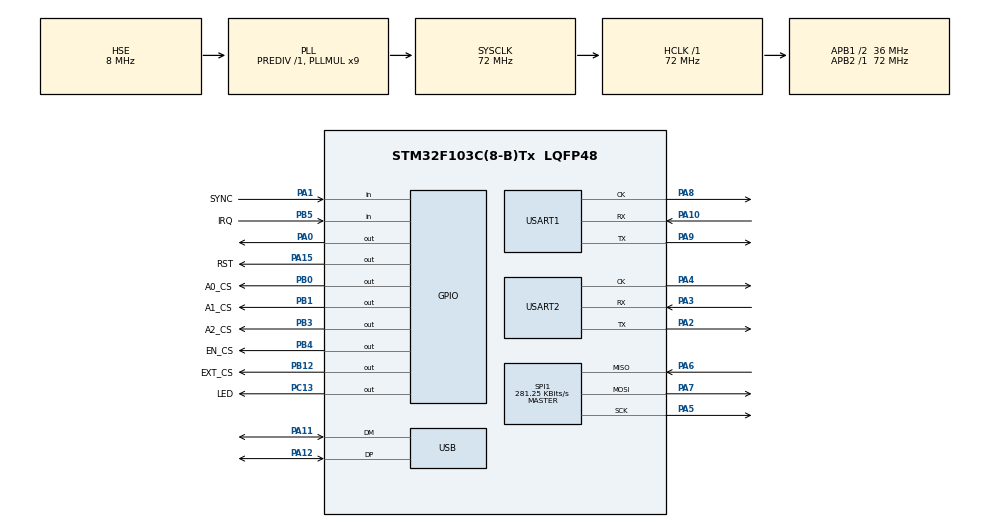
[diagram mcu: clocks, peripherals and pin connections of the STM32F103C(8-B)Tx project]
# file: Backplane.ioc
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Mcu.Family=STM32F1
Mcu.Name=STM32F103C(8-B)Tx
Mcu.Package=LQFP48
NVIC.PriorityGroup=NVIC_PRIORITYGROUP_4
NVIC.USB_LP_CAN1_RX0_IRQn=true\:0\:0\:false\:false\:true\:false\:true\:true
PA0-WKUP.Signal=GPIO_Output
PA1.GPIO_Label=SYNC
PA1.Signal=GPIO_Input
PA10.Mode=Synchronous
PA10.Signal=USART1_RX
PA11.Mode=Device
PA11.Signal=USB_DM
PA12.Mode=Device
PA12.Signal=USB_DP
PA13.Mode=Serial_Wire
PA13.Signal=SYS_JTMS-SWDIO
PA14.Mode=Serial_Wire
PA14.Signal=SYS_JTCK-SWCLK
PA15.GPIO_Label=RST
PA15.Signal=GPIO_Output
PA2.Mode=Synchronous
PA2.Signal=USART2_TX
PA3.Mode=Synchronous
PA3.Signal=USART2_RX
PA4.Mode=Synchronous
PA4.Signal=USART2_CK
PA5.Mode=Full_Duplex_Master
PA5.Signal=SPI1_SCK
PA6.Mode=Full_Duplex_Master
PA6.Signal=SPI1_MISO
PA7.Mode=Full_Duplex_Master
PA7.Signal=SPI1_MOSI
PA8.Mode=Synchronous
PA8.Signal=USART1_CK
PA9.Mode=Synchronous
PA9.Signal=USART1_TX
PB0.GPIO_Label=A0_CS
PB0.Signal=GPIO_Output
PB1.GPIO_Label=A1_CS
PB1.Signal=GPIO_Output
PB10.Signal=I2C2_SCL
PB11.Signal=I2C2_SDA
PB12.GPIO_Label=EXT_CS
PB12.Signal=GPIO_Output
PB13.Signal=SPI2_SCK
PB14.Signal=SPI2_MISO
PB15.Signal=SPI2_MOSI
PB3.GPIO_Label=A2_CS
PB3.Signal=GPIO_Output
PB4.GPIO_Label=EN_CS
PB4.Signal=GPIO_Output
PB5.GPIO_Label=IRQ
PB5.Signal=GPIO_Input
PB6.Signal=I2C1_SCL
PB7.Signal=I2C1_SDA
PC13-TAMPER-RTC.GPIO_Label=LED
PC13-TAMPER-RTC.Signal=GPIO_Output
PC14-OSC32_IN.Mode=LSE-External-Oscillator
PC14-OSC32_IN.Signal=RCC_OSC32_IN
PC15-OSC32_OUT.Mode=LSE-External-Oscillator
PC15-OSC32_OUT.Signal=RCC_OSC32_OUT
PD0-OSC_IN.Mode=HSE-External-Oscillator
PD0-OSC_IN.Signal=RCC_OSC_IN
PD1-OSC_OUT.Mode=HSE-External-Oscillator
PD1-OSC_OUT.Signal=RCC_OSC_OUT
ProjectManager.HeapSize=0x200
ProjectManager.StackSize=0x400
ProjectManager.TargetToolchain=STM32CubeIDE
RCC.AHBFreq_Value=72000000
RCC.APB1CLKDivider=RCC_HCLK_DIV2
RCC.APB1Freq_Value=36000000
RCC.APB1TimFreq_Value=72000000
RCC.APB2Freq_Value=72000000
RCC.APB2TimFreq_Value=72000000
RCC.HCLKFreq_Value=72000000
RCC.PLLMUL=RCC_PLL_MUL9
RCC.RTCClockSelection=RCC_RTCCLKSOURCE_LSE
RCC.SYSCLKFreq_VALUE=72000000
RCC.SYSCLKSource=RCC_SYSCLKSOURCE_PLLCLK
RCC.USBFreq_Value=48000000
RCC.USBPrescaler=RCC_USBCLKSOURCE_PLL_DIV1_5
SPI1.BaudRatePrescaler=SPI_BAUDRATEPRESCALER_256
SPI1.CalculateBaudRate=281.25 KBits/s
SPI1.Direction=SPI_DIRECTION_2LINES
SPI1.Mode=SPI_MODE_MASTER
SPI1.VirtualType=VM_MASTER
USART1.VirtualMode=VM_SYNC
USART2.VirtualMode=VM_SYNC
USB_DEVICE.CLASS_NAME_FS=CDC
USB_DEVICE.USBD_SELF_POWERED=0
USB_DEVICE.VirtualMode=Cdc
USB_DEVICE.VirtualModeFS=Cdc_FS
VP_RTC_No_RTC_Output.Mode=RTC_OUT_NO
VP_RTC_VS_RTC_Activate.Mode=RTC_Enabled
VP_USB_DEVICE_VS_USB_DEVICE_CDC_FS.Mode=CDC_FS
board=custom

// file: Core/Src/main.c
/* USER CODE BEGIN Header */
/**
  ******************************************************************************
  * @file           : main.c
  * @brief          : Main program body
  ******************************************************************************
  * @attention
  *
  * Copyright (c) 2026 STMicroelectronics.
  * All rights reserved.
  *
  * This software is licensed under terms that can be found in the LICENSE file
  * in the root directory of this software component.
  * If no LICENSE file comes with this software, it is provided AS-IS.
  *
  ******************************************************************************
  */
/* USER CODE END Header */
#include "main.h"
#include "rtc.h"
#include "spi.h"
#include "usart.h"
#include "usb_device.h"
#include "gpio.h"

/* USER CODE BEGIN Includes */
#include "interface.h"
#include "schedule.h"
/* USER CODE END Includes */

void SystemClock_Config(void);

/* USER CODE BEGIN 0 */
int miso_read_constant_test(uint8_t card)
{
    uint8_t tx[2] = {0x00, 0x00};   // clock 2 bytes
    uint8_t rx[2] = {0x00, 0x00};

    setCS(card);
    HAL_StatusTypeDef st = HAL_SPI_TransmitReceive(&hspi1, tx, rx, 2, 100);
    resetCS(); // or resetCS(); depending on your function signature

    if (st != HAL_OK) return 0;

    // Check 2nd byte (pipeline)
    return (rx[1] == 0xA5) ? 1 : 0;
}

/* USER CODE END 0 */

int main(void)
{

  /* MCU Configuration--------------------------------------------------------*/

  /* Reset of all peripherals, Initializes the Flash interface and the Systick. */
  HAL_Init();

  /* Configure the system clock */
  SystemClock_Config();

  /* Initialize all configured peripherals */
  MX_GPIO_Init();
  MX_USART1_Init();
  MX_USART2_Init();
  MX_RTC_Init();
  MX_SPI1_Init();
  MX_USB_DEVICE_Init();
  /* USER CODE BEGIN 2 */
  resetCS();
  uint8_t card = 1;
  /* USER CODE END 2 */

  /* Infinite loop */
  while (1)
  {

    /* USER CODE BEGIN 3 */
	  usb_protocol_poll(card);
  }
  /* USER CODE END 3 */
}

void SystemClock_Config(void)
{
  RCC_OscInitTypeDef RCC_OscInitStruct = {0};
  RCC_ClkInitTypeDef RCC_ClkInitStruct = {0};
  RCC_PeriphCLKInitTypeDef PeriphClkInit = {0};

  /** Initializes the RCC Oscillators according to the specified parameters
  * in the RCC_OscInitTypeDef structure.
  */
  RCC_OscInitStruct.OscillatorType = RCC_OSCILLATORTYPE_HSE|RCC_OSCILLATORTYPE_LSE;
  RCC_OscInitStruct.HSEState = RCC_HSE_ON;
  RCC_OscInitStruct.HSEPredivValue = RCC_HSE_PREDIV_DIV1;
  RCC_OscInitStruct.LSEState = RCC_LSE_ON;
  RCC_OscInitStruct.HSIState = RCC_HSI_ON;
  RCC_OscInitStruct.PLL.PLLState = RCC_PLL_ON;
  RCC_OscInitStruct.PLL.PLLSource = RCC_PLLSOURCE_HSE;
  RCC_OscInitStruct.PLL.PLLMUL = RCC_PLL_MUL9;
  if (HAL_RCC_OscConfig(&RCC_OscInitStruct) != HAL_OK)
  {
    Error_Handler();
  }

  /** Initializes the CPU, AHB and APB buses clocks
  */
  RCC_ClkInitStruct.ClockType = RCC_CLOCKTYPE_HCLK|RCC_CLOCKTYPE_SYSCLK
                              |RCC_CLOCKTYPE_PCLK1|RCC_CLOCKTYPE_PCLK2;
  RCC_ClkInitStruct.SYSCLKSource = RCC_SYSCLKSOURCE_PLLCLK;
  RCC_ClkInitStruct.AHBCLKDivider = RCC_SYSCLK_DIV1;
  RCC_ClkInitStruct.APB1CLKDivider = RCC_HCLK_DIV2;
  RCC_ClkInitStruct.APB2CLKDivider = RCC_HCLK_DIV1;

  if (HAL_RCC_ClockConfig(&RCC_ClkInitStruct, FLASH_LATENCY_2) != HAL_OK)
  {
    Error_Handler();
  }
  PeriphClkInit.PeriphClockSelection = RCC_PERIPHCLK_RTC|RCC_PERIPHCLK_USB;
  PeriphClkInit.RTCClockSelection = RCC_RTCCLKSOURCE_LSE;
  PeriphClkInit.UsbClockSelection = RCC_USBCLKSOURCE_PLL_DIV1_5;
  if (HAL_RCCEx_PeriphCLKConfig(&PeriphClkInit) != HAL_OK)
  {
    Error_Handler();
  }
}

void Error_Handler(void)
{
  __disable_irq();
  while (1)
  {
  }
}
